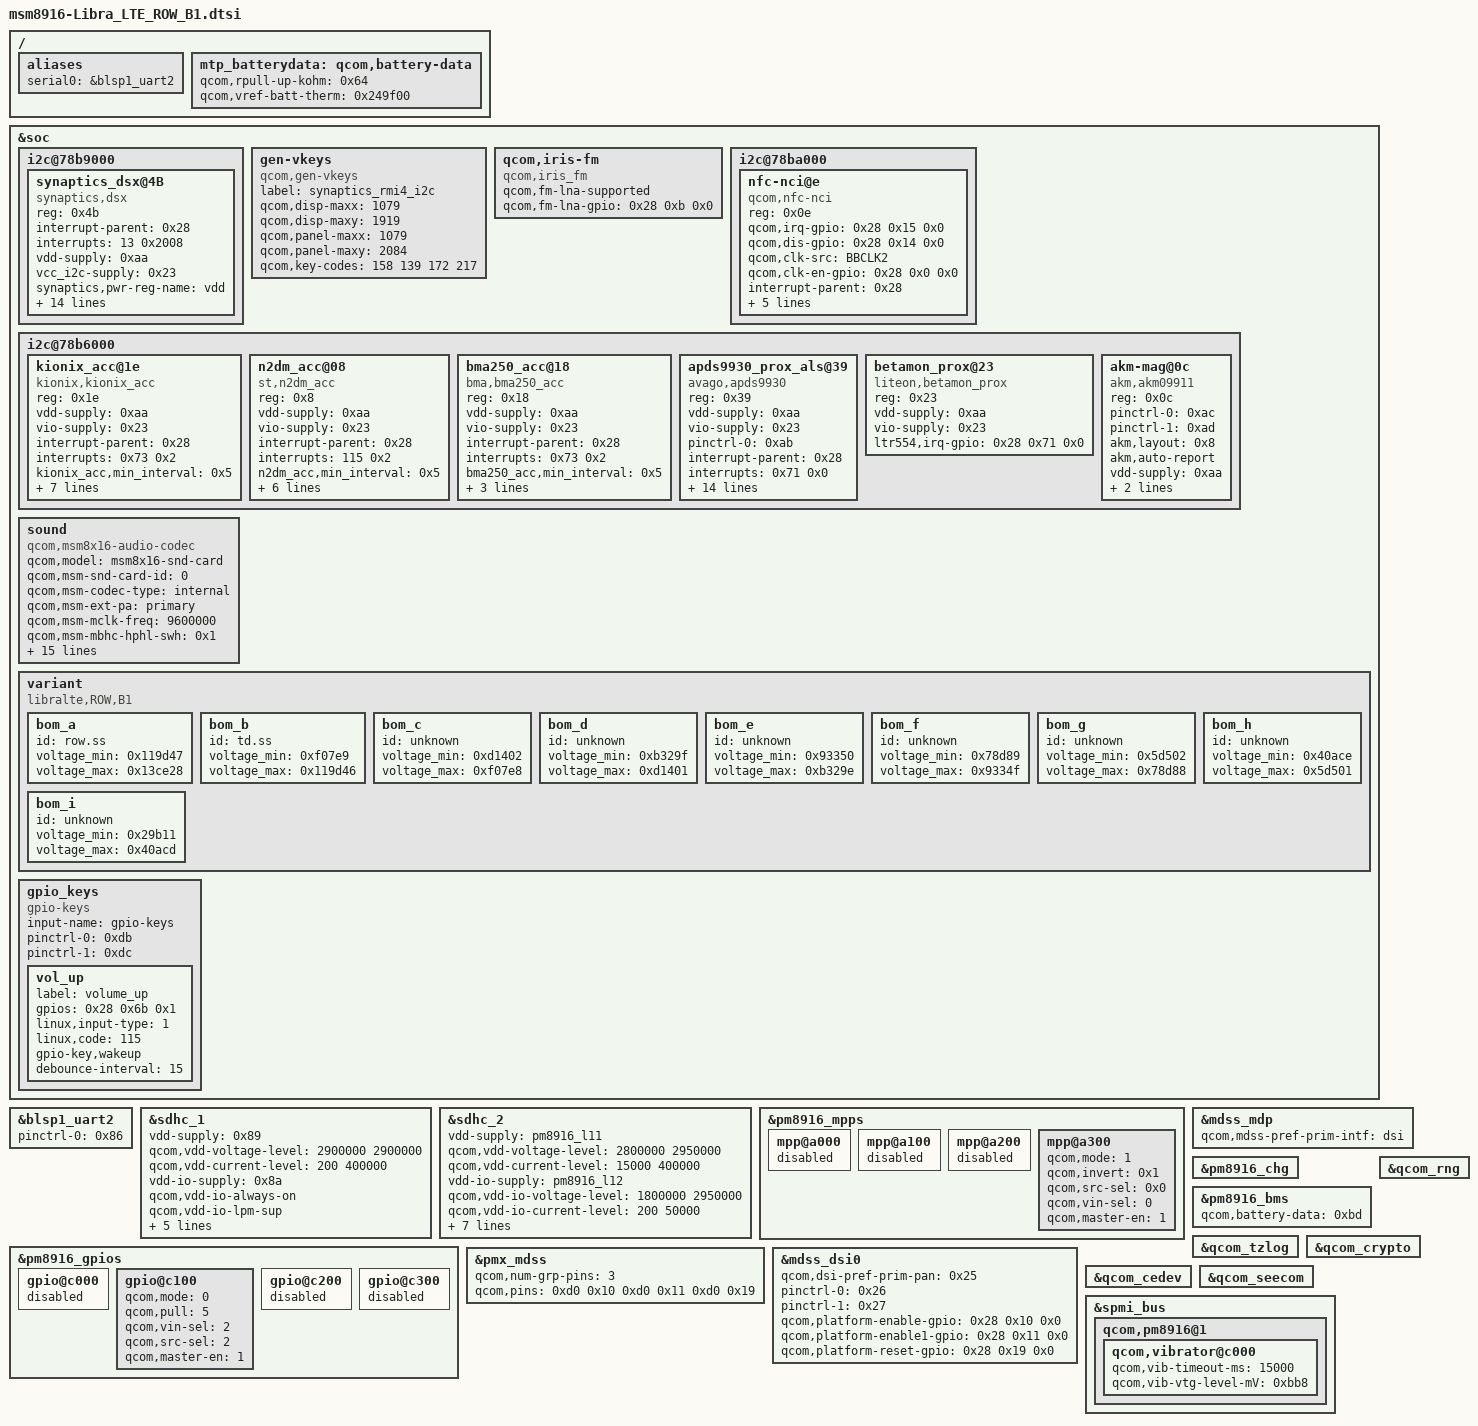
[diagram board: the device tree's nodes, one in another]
/* Copyright (c) 2014, The Linux Foundation. All rights reserved.
 *
 * This program is free software; you can redistribute it and/or modify
 * it under the terms of the GNU General Public License version 2 and
 * only version 2 as published by the Free Software Foundation.
 *
 * This program is distributed in the hope that it will be useful,
 * but WITHOUT ANY WARRANTY; without even the implied warranty of
 * MERCHANTABILITY or FITNESS FOR A PARTICULAR PURPOSE.  See the
 * GNU General Public License for more details.
 */

#include "msm8916.dtsi"
#include "msm8916-pinctrl.dtsi"
#include "msm8916-camera-sensor-mtp.dtsi"
#include "dsi_giza_720p_video-Libra_LTE_ROW_B1.dtsi"
#include "dsi_innolux_720p_video-Libra_LTE_ROW_B1.dtsi"

/ {
	aliases {
		serial0 = &blsp1_uart2;
	};
};

&soc {
	i2c@78b9000 { /* BLSP1 QUP5 */
		synaptics_dsx@4B {
			compatible = "synaptics,dsx";
			reg = <0x4b>;
			interrupt-parent = <0x28>;
			interrupts = <13 0x2008>;
			vdd-supply = <0xaa>;
			vcc_i2c-supply = <0x23>;
			synaptics,pwr-reg-name = "vdd";
			synaptics,bus-reg-name = "vcc_i2c";
			synaptics,irq-gpio = <0x28 0xd 0x2008>;
			synaptics,irq-flags = <0x2008>;
			synaptics,power-delay-ms = <0xa0>;
			synaptics,reset-gpio = <0x28 0xc 0x0>;
			synaptics,reset-on-state = <0x0>;
			synaptics,reset-active-ms = <0xa>;
			synaptics,reset-delay-ms = <0x64>;
			synaptics,cap-button-codes = <0x9e 0xac>;
			synaptics,firmware-name = "synaptics/libralte_fw_update";
			synaptics,max-y-for-2d = <0x500>;
			synaptics,vir-button-codes = <0x9e 0xb4 0x578 0x64 0x3c 0xac 0x21c 0x578 0x64 0x3c>;
		};
	};

	gen-vkeys {
		compatible = "qcom,gen-vkeys";
		label = "synaptics_rmi4_i2c";
		qcom,disp-maxx = <1079>;
		qcom,disp-maxy = <1919>;
		qcom,panel-maxx = <1079>;
		qcom,panel-maxy = <2084>;
		qcom,key-codes = <158 139 172 217>;
	};

	qcom,iris-fm {
		compatible = "qcom,iris_fm";
		qcom,fm-lna-supported;
		qcom,fm-lna-gpio = <0x28 0xb 0x0>;
	};

	i2c@78ba000 { /* BLSP1 QUP6 */
		nfc-nci@e {
			compatible = "qcom,nfc-nci";
			reg = <0x0e>;
			qcom,irq-gpio = <0x28 0x15 0x0>;
			qcom,dis-gpio = <0x28 0x14 0x0>;
			qcom,clk-src = "BBCLK2";
			qcom,clk-en-gpio = <0x28 0x0 0x0>;
			interrupt-parent = <0x28>;
			interrupts = <21 0>;
			interrupt-names = "nfc_irq";
			pinctrl-names = "nfc_active","nfc_suspend";
			pinctrl-0 = <0xb2 0xb3>;
			pinctrl-1 = <0xb4 0xb5>;
			qcom,clk-gpio = <0xb6 0x2 0x0>;
			clocks = <0x8 0xfe15cb87>;
			clock-names = "ref_clk";
		};
	};

	i2c@78b6000 { /* BLSP1 QUP2 */
		kionix_acc@1e {
			reg = <0x1e>;
			compatible = "kionix,kionix_acc";
			vdd-supply = <0xaa>;
			vio-supply = <0x23>;
			interrupt-parent = <0x28>;
			interrupts = <0x73 0x2>;
			kionix_acc,min_interval = <0x5>;
			kionix_acc,poll_interval = <0xc8>;
			kionix_acc,accel_direction = <0x2>;
			kionix_acc,accel_irq_use_ddtap = <0x1>;
			kionix_acc,accel_res = <0x3>;
			kionix_acc,accel_g_range = <0x0>;
			kionix_acc,accel_tap_z_direction = <0x1>;
			kionix_acc,accel_dtap_z_direction = <0x1>;
		};

		n2dm_acc@08 {
			reg = <0x8>;
			compatible = "st,n2dm_acc";
			vdd-supply = <0xaa>;
			vio-supply = <0x23>;
			interrupt-parent = <0x28>;
			interrupts = <115 0x2>;
			n2dm_acc,min_interval = <0x5>;
			n2dm_acc,poll_interval = <0xc8>;
			n2dm_acc,accel_direction = <0x2>;
			n2dm_acc,accel_irq_use_ddtap = <0x1>;
			n2dm_acc,accel_g_range = <0x0>;
			n2dm_acc,accel_tap_z_direction = <0x1>;
			n2dm_acc,accel_dtap_z_direction = <0x1>;
		};

		bma250_acc@18 {
			reg = <0x18>;
			compatible = "bma,bma250_acc";
			vdd-supply = <0xaa>;
			vio-supply = <0x23>;
			interrupt-parent = <0x28>;
			interrupts = <0x73 0x2>;
			bma250_acc,min_interval = <0x5>;
			bma250_acc,poll_interval = <0xc8>;
			bma250_acc,accel_direction = <0x2>;
			bma250_acc,accel_g_range = <0x3>;
		};

		apds9930_prox_als@39 {
			reg = <0x39>;
			compatible = "avago,apds9930";
			vdd-supply = <0xaa>;
		        vio-supply = <0x23>;
			pinctrl-names = "default";
			pinctrl-0 = <0xab>;
			interrupt-parent = <0x28>;
			interrupts = <0x71 0x0>;
			apds9930,irq-gpio = <0x28 0x71 0x0>;
			apds9930,ps_detection_threshold = <0x2c4>;
			apds9930,ps_hsythresis_threshold = <0x1ca>;
			apds9930,ps_pulse_number = <0x3>;
			apds9930,ps_pdrive_ma = <0x40>;
			apds9930,ps_pgain = <0x8>;
			apds9930,ps_poffset = <0x0>;
			apds9930,als_threshold_hsytersis = <0x14>;
			apds9930,als_use_irq_in_idle = <0x1>;
			apds9930,als_ga = <0x898>;
			apds9930,als_coe_b = <0xba>;
			apds9930,als_coe_c = <0x52>;
			apds9930,als_coe_d = <0x74>;
			apds9930,als_df = <0x34>;
		};

		betamon_prox@23 {
			reg = <0x23>;
			compatible = "liteon,betamon_prox";
			vdd-supply = <0xaa>;
			vio-supply = <0x23>;
			ltr554,irq-gpio = <0x28 0x71 0x0>;
		};

		akm-mag@0c {
			reg = <0x0c>;
			compatible = "akm,akm09911";
			pinctrl-names = "default", "sleep";
			pinctrl-0 = <0xac>;
			pinctrl-1 = <0xad>;
			akm,layout = <0x8>;
			akm,auto-report;
			vdd-supply = <0xaa>;
			vio-supply = <0x23>;
			akm,gpio_rstn = <0x28 0x45 0x0>;
		};

	};

	sound {
		compatible = "qcom,msm8x16-audio-codec";
		qcom,model = "msm8x16-snd-card";
		qcom,msm-snd-card-id = <0>;
		qcom,msm-codec-type = "internal";
		qcom,msm-ext-pa = "primary";
		qcom,msm-mclk-freq = <9600000>;
		qcom,msm-mbhc-hphl-swh = <0x1>;
		qcom,msm-mbhc-gnd-swh = <0>;
		qcom,msm-hs-micbias-type = "internal";
		qcom,audio-routing =
			"RX_BIAS", "MCLK",
			"SPK_RX_BIAS", "MCLK",
			"INT_LDO_H", "MCLK",
			"MIC BIAS External", "Handset Mic",
			"MIC BIAS Internal2", "Headset Mic",
			"MIC BIAS External", "Secondary Mic",
			"AMIC1", "MIC BIAS External",
			"AMIC2", "MIC BIAS Internal2",
			"AMIC3", "MIC BIAS External";
		pinctrl-names = "cdc_lines_act",
				"cdc_lines_sus",
				"cdc_lines_sec_ext_act",
				"cdc_lines_sec_ext_sus",
				"cross_conn_det_act",
				"cross_conn_det_sus";
		pinctrl-0 = <0xd3>;
		pinctrl-1 = <0xd4>;
		pinctrl-2 = <0xd3 0xd5 0xd6>;
		pinctrl-3 = <0xd4 0xd7 0xd8>;
		pinctrl-4 = <0xd9>;
		pinctrl-5 = <0xda>;
	};
};

&blsp1_uart2 {
	status = "ok";
	pinctrl-names = "default";
	pinctrl-0 = <0x86>;
};

&soc {
        variant {
		compatible = "libralte,ROW,B1";

		bom_a {
			id = "row.ss";
			voltage_min = <0x119d47>;
			voltage_max = <0x13ce28>;
		};

		bom_b {
			id = "td.ss";
			voltage_min = <0xf07e9>;
			voltage_max = <0x119d46>;
	        };

		bom_c {
			id = "unknown";
			voltage_min = <0xd1402>;
			voltage_max = <0xf07e8>;
		};

		bom_d {
			id = "unknown";
			voltage_min = <0xb329f>;
			voltage_max = <0xd1401>;
		};

		bom_e {
			id = "unknown";
			voltage_min = <0x93350>;
			voltage_max = <0xb329e>;
		};

		bom_f {
			id = "unknown";
			voltage_min = <0x78d89>;
			voltage_max = <0x9334f>;
		};

		bom_g {
			id = "unknown";
			voltage_min = <0x5d502>;
			voltage_max = <0x78d88>;
		};

		bom_h {
			id = "unknown";
			voltage_min = <0x40ace>;
			voltage_max = <0x5d501>;
		};

		bom_i {
			id = "unknown";
			voltage_min = <0x29b11>;
			voltage_max = <0x40acd>;
		};
	};

	gpio_keys {
		compatible = "gpio-keys";
		input-name = "gpio-keys";
		pinctrl-names = "tlmm_gpio_key_active", "tlmm_gpio_key_suspend";
		pinctrl-0 = <0xdb>;
		pinctrl-1 = <0xdc>;

		vol_up {
			label = "volume_up";
			gpios = <0x28 0x6b 0x1>;
			linux,input-type = <1>;
			linux,code = <115>;
			gpio-key,wakeup;
			debounce-interval = <15>;
		};
	};
};

&sdhc_1 {
	vdd-supply = <0x89>;
	qcom,vdd-voltage-level = <2900000 2900000>;
	qcom,vdd-current-level = <200 400000>;

	vdd-io-supply = <0x8a>;
	qcom,vdd-io-always-on;
	qcom,vdd-io-lpm-sup;
	qcom,vdd-io-voltage-level = <1800000 1800000>;
	qcom,vdd-io-current-level = <200 60000>;

	pinctrl-names = "active", "sleep";
	pinctrl-0 = <0x8b 0x8c 0x8d>;
	pinctrl-1 = <0x8e 0x8f 0x90>;

	qcom,nonremovable;

	status = "ok";
};

&sdhc_2 {
	vdd-supply = <&pm8916_l11>;
	qcom,vdd-voltage-level = <2800000 2950000>;
	qcom,vdd-current-level = <15000 400000>;

	vdd-io-supply = <&pm8916_l12>;
	qcom,vdd-io-voltage-level = <1800000 2950000>;
	qcom,vdd-io-current-level = <200 50000>;

	pinctrl-names = "active", "sleep";
	pinctrl-0 = <0x91 0x92 0x93 0x94>;
	pinctrl-1 = <0x95 0x96 0x97 0x98>;

	#address-cells = <0>;
	interrupt-parent = <0x99>;
	interrupts = <0 1>;
	#interrupt-cells = <1>;
	interrupt-map-mask = <0xffffffff>;
	interrupt-names = "hc_irq", "pwr_irq";
	interrupt-map = <0x0 0x1 0x0 0x7d 0x0 0x1 0x1 0x0 0xdd 0x0>;

	status = "ok";
};

&pm8916_mpps {
	mpp@a000 { /* MPP 1 */
		/* VDD_PX */
		status = "disabled";
	};

	mpp@a100 { /* MPP 2 */
		/* HR LED */
		status = "disabled";
	};

	mpp@a200 { /* MPP 3 */
		/* VREF DAC */
		status = "disabled";
	};

	mpp@a300 { /* MPP 4 */
		/* Backlight PWM */
		qcom,mode = <1>;		/* Digital output */
		qcom,invert = <0x1>;		/* Disable invert */
		qcom,src-sel = <0x0>;		/* DTEST1 */
		qcom,vin-sel = <0>;		/* VPH_PWR */
		qcom,master-en = <1>;		/* Enable MPP */
	};
};

&pm8916_gpios {
	gpio@c000 { /* GPIO 1 */
		/* Battery UICC Alarm */
		status = "disabled";
	};

	gpio@c100 { /* GPIO 2 */
		/* NFC_CLK_REQ */
		qcom,mode = <0>; /* QPNP_PIN_MODE_DIG_IN */
		qcom,pull = <5>; /* QPNP_PIN_PULL_NO */
		qcom,vin-sel = <2>; /* QPNP_PIN_VIN2 */
		qcom,src-sel = <2>; /* QPNP_PIN_SEL_FUNC_1 */
		qcom,master-en = <1>;
	};

	gpio@c200 { /* GPIO 3 */
		/* External regulator control for WTR */
		status = "disabled";
	};

	gpio@c300 { /* GPIO 4 */
		/* External regulator control for APC */
		status = "disabled";
	};
};

&mdss_mdp {
	qcom,mdss-pref-prim-intf = "dsi";
};

&pmx_mdss {
	qcom,num-grp-pins = <3>;
        qcom,pins = <0xd0 0x10 0xd0 0x11 0xd0 0x19>;
};

&mdss_dsi0 {
	qcom,dsi-pref-prim-pan = <0x25>;
	pinctrl-names = "mdss_default", "mdss_sleep";
	pinctrl-0 = <0x26>;
	pinctrl-1 = <0x27>;
	qcom,platform-enable-gpio = <0x28 0x10 0x0>;
	qcom,platform-enable1-gpio = <0x28 0x11 0x0>;
	qcom,platform-reset-gpio = <0x28 0x19 0x0>;
};

&pm8916_chg {
	status = "ok";
};

/ {
	mtp_batterydata: qcom,battery-data {
		qcom,rpull-up-kohm = <0x64>;
		qcom,vref-batt-therm = <0x249f00>;

		#include "batterydata-nokia-BV_L5C-2400mAh-Libra_LTE_ROW_B1.dtsi"
	};
};

&pm8916_bms {
	status = "ok";
	qcom,battery-data = <0xbd>;
};

&qcom_tzlog {
	status = "okay";
};

&qcom_rng {
	status = "okay";
};

&qcom_crypto {
	status = "okay";
};

&qcom_cedev {
	status = "okay";
};

&qcom_seecom {
	status = "okay";
};

/* CoreSight */
&spmi_bus {
	qcom,pm8916@1 {
		qcom,vibrator@c000 {
			status = "okay";
			qcom,vib-timeout-ms = <15000>;
			qcom,vib-vtg-level-mV = <0xbb8>;
		};
	};
};
